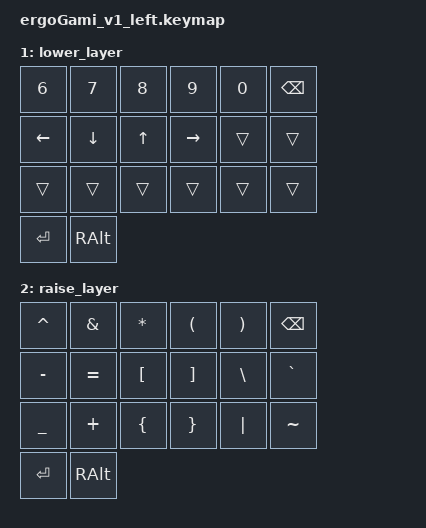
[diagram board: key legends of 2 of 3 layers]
/*
 * Copyright (c) 2020 The ZMK Contributors
 *
 * SPDX-License-Identifier: MIT
 */

#include <behaviors.dtsi>
#include <dt-bindings/zmk/keys.h>
#include <dt-bindings/zmk/bt.h>

/ {
        keymap {
                compatible = "zmk,keymap";

                default_layer {
// -----------------------------------------------------------------------------------------
// |  Q  |  W  |  E  |  R  |  T  |   |  Y  |  U   |  I  |  O  |  P  |
// |  A  |  S  |  D  |  F  |  G  |   |  H  |  J   |  K  |  L  |  ;  |
// |  Z  |  X  |  C  |  V  |  B  |   |  N  |  M   |  ,  |  .  |  /  |
//             | GUI | LWR | SPC |   | ENT | RSE  | ALT |
                        bindings = <
                                &kp Y &kp U    &kp I     &kp O   &kp P
                                &kp H &kp J    &kp K     &kp L   &kp SEMI
                                &kp N &kp M    &kp COMMA &kp DOT &kp FSLH
                                &mo 2 &kp RALT
                        >;
                };
                lower_layer {
// -----------------------------------------------------------------------------------------
// |  TAB |  1  |  2  |  3  |  4  |  5  |   |  6  |  7  |  8  |  9  |  0  | BSPC |
// | BTCLR| BT1 | BT2 | BT3 | BT4 | BT5 |   | LFT | DWN |  UP | RGT |     |      |
// | SHFT |     |     |     |     |     |   |     |     |     |     |     |      |
//                    | GUI |     | SPC |   | ENT |     | ALT |
                        bindings = <
                                &kp N6   &kp N7   &kp N8 &kp N9    &kp N0 &kp BSPC
                                &kp LEFT &kp DOWN &kp UP &kp RIGHT &trans &trans
                                &trans   &trans   &trans &trans    &trans &trans
                                &kp RET  &kp RALT
                        >;
                };

                raise_layer {
// -----------------------------------------------------------------------------------------
// |  TAB |  !  |  @  |  #  |  $  |  %  |   |  ^  |  &  |  *  |  (  |  )  | BSPC |
// | CTRL |     |     |     |     |     |   |  -  |  =  |  [  |  ]  |  \  |  `   |
// | SHFT |     |     |     |     |     |   |  _  |  +  |  {  |  }  | "|" |  ~   |
//                    | GUI |     | SPC |   | ENT |     | ALT |
                        bindings = <
                                &kp CARET &kp AMPS  &kp ASTRK &kp LPAR &kp RPAR &kp BSPC
                                &kp MINUS &kp EQUAL &kp LBKT  &kp RBKT &kp BSLH &kp GRAVE
                                &kp UNDER &kp PLUS  &kp LBRC  &kp RBRC &kp PIPE &kp TILDE
                                &kp RET   &kp RALT
                        >;
                };
        };
};
